# STM32WB30_CM4 register map
File version: 1.4-IAR
CPU: CM4 r0p1, little endian, MPU, FPU, 4 interrupt priority bits
Registers are 32-bit, read-write, reset 0x0 unless marked. A register's access mark holds for its fields unless they carry their own. Offsets are from the block's base; [hi:lo] are bit positions; {n}, {i} and the like mark numbered series.

## I2C1 — Inter-integrated circuit
Base 0x40005400
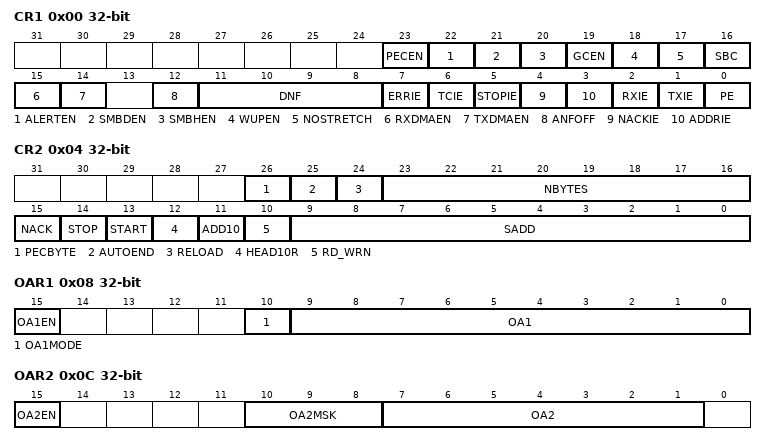
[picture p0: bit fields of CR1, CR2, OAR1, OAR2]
0x00 CR1 — Control register 1
  [23] PECEN — PEC enable
  [22] ALERTEN — SMBUS alert enable
  [21] SMBDEN — SMBus Device Default address enable
  [20] SMBHEN — SMBus Host address enable
  [19] GCEN — General call enable
  [18] WUPEN — Wakeup from STOP enable
  [17] NOSTRETCH — Clock stretching disable
  [16] SBC — Slave byte control
  [15] RXDMAEN — DMA reception requests enable
  [14] TXDMAEN — DMA transmission requests enable
  [12] ANFOFF — Analog noise filter OFF
  [11:8] DNF — Digital noise filter
  [7] ERRIE — Error interrupts enable
  [6] TCIE — Transfer Complete interrupt enable
  [5] STOPIE — STOP detection Interrupt enable
  [4] NACKIE — Not acknowledge received interrupt enable
  [3] ADDRIE — Address match interrupt enable (slave only)
  [2] RXIE — RX Interrupt enable
  [1] TXIE — TX Interrupt enable
  [0] PE — Peripheral enable
0x04 CR2 — Control register 2
  [26] PECBYTE — Packet error checking byte
  [25] AUTOEND — Automatic end mode (master mode)
  [24] RELOAD — NBYTES reload mode
  [23:16] NBYTES — Number of bytes
  [15] NACK — NACK generation (slave mode)
  [14] STOP — Stop generation (master mode)
  [13] START — Start generation
  [12] HEAD10R — 10-bit address header only read direction (master receiver mode)
  [11] ADD10 — 10-bit addressing mode (master mode)
  [10] RD_WRN — Transfer direction (master mode)
  [9:0] SADD — Slave address bit (master mode)
0x08 OAR1 — Own address register 1
  [15] OA1EN — Own Address 1 enable
  [10] OA1MODE — Own Address 1 10-bit mode
  [9:0] OA1 — Interface address
0x0C OAR2 — Own address register 2
  [15] OA2EN — Own Address 2 enable
  [10:8] OA2MSK — Own Address 2 masks
  [7:1] OA2 — Interface address
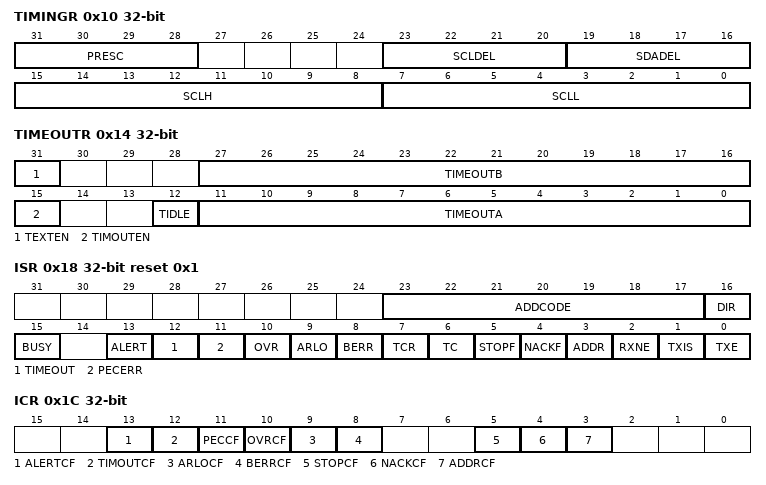
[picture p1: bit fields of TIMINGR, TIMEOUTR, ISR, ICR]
0x10 TIMINGR — Timing register
  [31:28] PRESC — Timing prescaler
  [23:20] SCLDEL — Data setup time
  [19:16] SDADEL — Data hold time
  [15:8] SCLH — SCL high period (master mode)
  [7:0] SCLL — SCL low period (master mode)
0x14 TIMEOUTR — Status register 1
  [31] TEXTEN — Extended clock timeout enable
  [27:16] TIMEOUTB — Bus timeout B
  [15] TIMOUTEN — Clock timeout enable
  [12] TIDLE — Idle clock timeout detection
  [11:0] TIMEOUTA — Bus timeout A
0x18 ISR access per field reset 0x1 — Interrupt and Status register
  [23:17] ADDCODE ro — Address match code (Slave mode)
  [16] DIR ro — Transfer direction (Slave mode)
  [15] BUSY ro — Bus busy
  [13] ALERT ro — SMBus alert
  [12] TIMEOUT ro — Timeout or t_low detection flag
  [11] PECERR ro — PEC Error in reception
  [10] OVR ro — Overrun/Underrun (slave mode)
  [9] ARLO ro — Arbitration lost
  [8] BERR ro — Bus error
  [7] TCR ro — Transfer Complete Reload
  [6] TC ro — Transfer Complete (master mode)
  [5] STOPF ro — Stop detection flag
  [4] NACKF ro — Not acknowledge received flag
  [3] ADDR ro — Address matched (slave mode)
  [2] RXNE ro — Receive data register not empty (receivers)
  [1] TXIS rw — Transmit interrupt status (transmitters)
  [0] TXE rw — Transmit data register empty (transmitters)
0x1C ICR wo — Interrupt clear register
  [13] ALERTCF — Alert flag clear
  [12] TIMOUTCF — Timeout detection flag clear
  [11] PECCF — PEC Error flag clear
  [10] OVRCF — Overrun/Underrun flag clear
  [9] ARLOCF — Arbitration lost flag clear
  [8] BERRCF — Bus error flag clear
  [5] STOPCF — Stop detection flag clear
  [4] NACKCF — Not Acknowledge flag clear
  [3] ADDRCF — Address Matched flag clear
0x20 PECR ro — PEC register
  [7:0] PEC — Packet error checking register
0x24 RXDR ro — Receive data register
  [7:0] RXDATA — 8-bit receive data
0x28 TXDR — Transmit data register
  [7:0] TXDATA — 8-bit transmit data

## IPCC
Base 0x58000C00
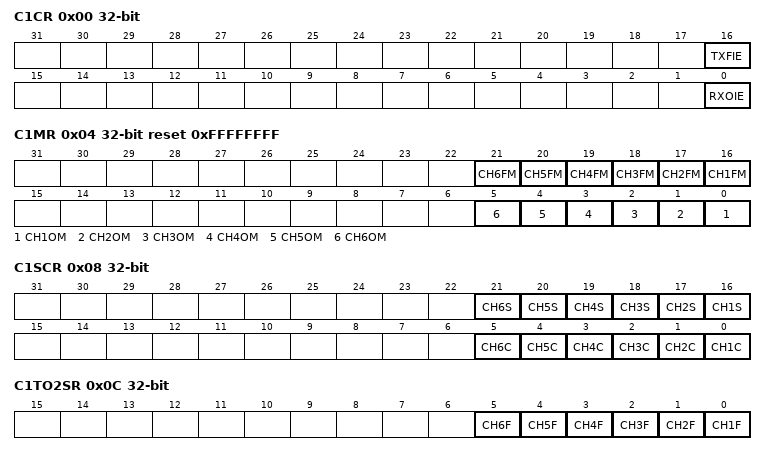
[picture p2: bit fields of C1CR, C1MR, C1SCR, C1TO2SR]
0x00 C1CR — Control register CPU1
  [16] TXFIE — processor 1 Transmit channel free interrupt enable
  [0] RXOIE — processor 1 Receive channel occupied interrupt enable
0x04 C1MR reset 0xFFFFFFFF — Mask register CPU1
  [n+15] CH{n}FM (n=1..6) — processor 1 Transmit channel {n} free interrupt mask
  [n-1] CH{n}OM (n=1..6) — processor 1 Receive channel {n} occupied interrupt enable
0x08 C1SCR wo — Status Set or Clear register CPU1
  [n+15] CH{n}S (n=1..6) — processor 1 Transmit channel {n} status set
  [n-1] CH{n}C (n=1..6) — processor 1 Receive channel {n} status clear
0x0C C1TO2SR ro — CPU1 to CPU2 status register
  [n-1] CH{n}F (n=1..6) — processor 1 transmit to process 2 Receive channel {n} status flag
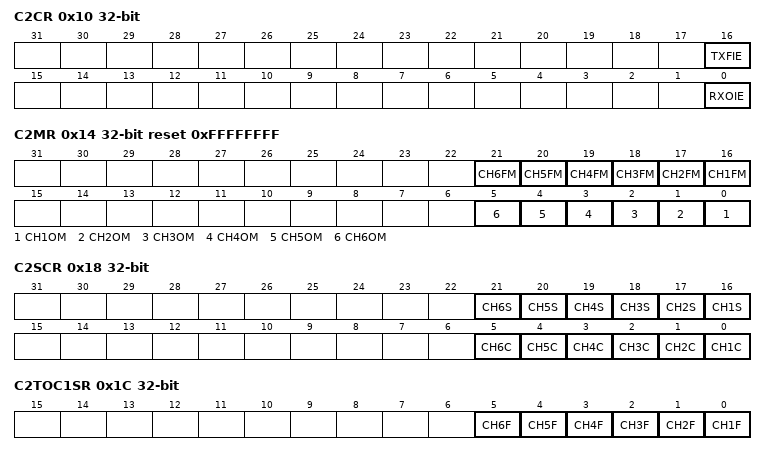
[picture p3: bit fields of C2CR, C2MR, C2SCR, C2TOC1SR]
0x10 C2CR — Control register CPU2
  [16] TXFIE — processor 2 Transmit channel free interrupt enable
  [0] RXOIE — processor 2 Receive channel occupied interrupt enable
0x14 C2MR reset 0xFFFFFFFF — Mask register CPU2
  [n+15] CH{n}FM (n=1..6) — processor 2 Transmit channel {n} free interrupt mask
  [n-1] CH{n}OM (n=1..6) — processor 2 Receive channel {n} occupied interrupt enable
0x18 C2SCR wo — Status Set or Clear register CPU2
  [n+15] CH{n}S (n=1..6) — processor 2 Transmit channel {n} status set
  [n-1] CH{n}C (n=1..6) — processor 2 Receive channel {n} status clear
0x1C C2TOC1SR ro — CPU2 to CPU1 status register
  [n-1] CH{n}F (n=1..6) — processor 2 transmit to process 1 Receive channel {n} status flag
0x3F0 HWCFGR ro reset 0x6 — IPCC Hardware configuration register
  [7:0] CHANNELS — Number of channels per CPU supported by the IP, range 1 to 16
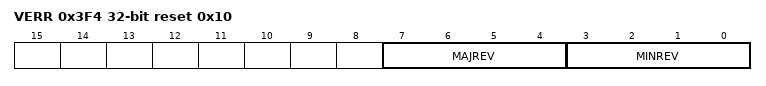
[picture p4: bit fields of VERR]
0x3F4 VERR ro reset 0x10 — IPCC version register
  [7:4] MAJREV — Major Revision
  [3:0] MINREV — Minor Revision
0x3F8 IPIDR ro reset 0x100071 — IPCC indentification register
  [31:0] IPID — Identification Code
0x3FC SIDR ro reset 0xA3C5DD01 — IPCC size indentification register
  [31:0] SID — Size Identification Code
